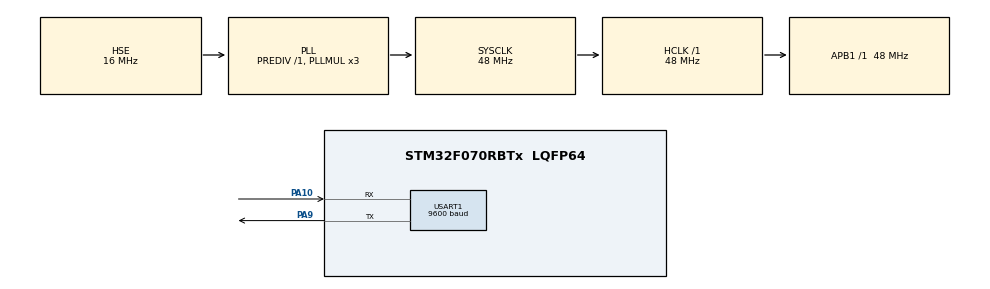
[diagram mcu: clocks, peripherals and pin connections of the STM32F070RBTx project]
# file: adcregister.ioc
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Mcu.Family=STM32F0
Mcu.Name=STM32F070RBTx
Mcu.Package=LQFP64
NVIC.USART1_IRQn=true\:0\:0\:false\:false\:true
PA10.Mode=Asynchronous
PA10.Signal=USART1_RX
PA9.Mode=Asynchronous
PA9.Signal=USART1_TX
PF0-OSC_IN.Mode=HSE-External-Oscillator
PF0-OSC_IN.Signal=RCC_OSC_IN
PF1-OSC_OUT.Mode=HSE-External-Oscillator
PF1-OSC_OUT.Signal=RCC_OSC_OUT
ProjectManager.HeapSize=0x200
ProjectManager.StackSize=0x400
ProjectManager.TargetToolchain=MDK-ARM V5
RCC.AHBFreq_Value=48000000
RCC.APB1Freq_Value=48000000
RCC.APB1TimFreq_Value=48000000
RCC.HCLKFreq_Value=48000000
RCC.HSE_VALUE=16000000
RCC.PLLMUL=RCC_PLL_MUL3
RCC.PLLSourceVirtual=RCC_PLLSOURCE_HSE
RCC.SYSCLKFreq_VALUE=48000000
RCC.SYSCLKSource=RCC_SYSCLKSOURCE_PLLCLK
USART1.BaudRate=9600
USART1.VirtualMode-Asynchronous=VM_ASYNC
USART1.WordLength=WORDLENGTH_8B
board=adcregister

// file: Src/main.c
/**
  ******************************************************************************
  * File Name          : main.c
  * Description        : Main program body
  ******************************************************************************
  ** This notice applies to any and all portions of this file
  * that are not between comment pairs USER CODE BEGIN and
  * USER CODE END. Other portions of this file, whether
  * inserted by the user or by software development tools
  * are owned by their respective copyright owners.
  *
  * COPYRIGHT(c) 2017 STMicroelectronics
  *
  * Redistribution and use in source and binary forms, with or without modification,
  * are permitted provided that the following conditions are met:
  *   1. Redistributions of source code must retain the above copyright notice,
  *      this list of conditions and the following disclaimer.
  *   2. Redistributions in binary form must reproduce the above copyright notice,
  *      this list of conditions and the following disclaimer in the documentation
  *      and/or other materials provided with the distribution.
  *   3. Neither the name of STMicroelectronics nor the names of its contributors
  *      may be used to endorse or promote products derived from this software
  *      without specific prior written permission.
  *
  * THIS SOFTWARE IS PROVIDED BY THE COPYRIGHT HOLDERS AND CONTRIBUTORS "AS IS"
  * AND ANY EXPRESS OR IMPLIED WARRANTIES, INCLUDING, BUT NOT LIMITED TO, THE
  * IMPLIED WARRANTIES OF MERCHANTABILITY AND FITNESS FOR A PARTICULAR PURPOSE ARE
  * DISCLAIMED. IN NO EVENT SHALL THE COPYRIGHT HOLDER OR CONTRIBUTORS BE LIABLE
  * FOR ANY DIRECT, INDIRECT, INCIDENTAL, SPECIAL, EXEMPLARY, OR CONSEQUENTIAL
  * DAMAGES (INCLUDING, BUT NOT LIMITED TO, PROCUREMENT OF SUBSTITUTE GOODS OR
  * SERVICES; LOSS OF USE, DATA, OR PROFITS; OR BUSINESS INTERRUPTION) HOWEVER
  * CAUSED AND ON ANY THEORY OF LIABILITY, WHETHER IN CONTRACT, STRICT LIABILITY,
  * OR TORT (INCLUDING NEGLIGENCE OR OTHERWISE) ARISING IN ANY WAY OUT OF THE USE
  * OF THIS SOFTWARE, EVEN IF ADVISED OF THE POSSIBILITY OF SUCH DAMAGE.
  *
  ******************************************************************************
  */
#include "main.h"
#include "stm32f0xx_hal.h"

UART_HandleTypeDef huart1;

/* USER CODE BEGIN PV */
/* Private variables ---------------------------------------------------------*/
int datain[10],len=0;
unsigned char buffer[100];
/* USER CODE END PV */

void SystemClock_Config(void);
static void MX_GPIO_Init(void);
static void MX_USART1_UART_Init(void);

/* USER CODE BEGIN PFP */
/* Private function prototypes -----------------------------------------------*/

/* USER CODE END PFP */

int main(void)
{

  /* MCU Configuration----------------------------------------------------------*/

  /* Reset of all peripherals, Initializes the Flash interface and the Systick. */
  HAL_Init();

  /* Configure the system clock */
  SystemClock_Config();

  /* Initialize all configured peripherals */
  MX_GPIO_Init();
  MX_USART1_UART_Init();

  /* USER CODE BEGIN 2 */

ADC1 ->CR =0X00000000;  //disable adc start
ADC1 ->CFGR1=0X00002000;  // disable watchdog
ADC1 ->CFGR2=0X00000000;
ADC1 ->SMPR=0X00000000;
ADC1 ->CHSELR=0X00000003;
ADC1 ->CR =0X00000005;   //start adc

  /* USER CODE END 2 */

  /* Infinite loop */
  while (1)
  {

  /* USER CODE BEGIN 3 */
if((ADC1 ->ISR) & 0x00000004)
{

	ADC1 ->ISR &= (~0x00000004);
	if(ADC1 ->CHSELR==0x00000001)
	{
	datain[0] = ADC1->DR;
	}
}
sprintf(buffer,"Value is %d",datain[0]);
len=strlen(buffer);
HAL_UART_Transmit(&huart1,buffer,len,10);
HAL_UART_Transmit(&huart1,"\r\n",1,10);
HAL_Delay(200);
  }
  /* USER CODE END 3 */

}

/** System Clock Configuration
*/
void SystemClock_Config(void)
{

  RCC_OscInitTypeDef RCC_OscInitStruct;
  RCC_ClkInitTypeDef RCC_ClkInitStruct;
  RCC_PeriphCLKInitTypeDef PeriphClkInit;

    /**Initializes the CPU, AHB and APB busses clocks
    */
  RCC_OscInitStruct.OscillatorType = RCC_OSCILLATORTYPE_HSE;
  RCC_OscInitStruct.HSEState = RCC_HSE_ON;
  RCC_OscInitStruct.HSIState = RCC_HSI_ON;
  RCC_OscInitStruct.PLL.PLLState = RCC_PLL_ON;
  RCC_OscInitStruct.PLL.PLLSource = RCC_PLLSOURCE_HSE;
  RCC_OscInitStruct.PLL.PLLMUL = RCC_PLL_MUL3;
  RCC_OscInitStruct.PLL.PREDIV = RCC_PREDIV_DIV1;
  if (HAL_RCC_OscConfig(&RCC_OscInitStruct) != HAL_OK)
  {
    _Error_Handler(__FILE__, __LINE__);
  }

    /**Initializes the CPU, AHB and APB busses clocks
    */
  RCC_ClkInitStruct.ClockType = RCC_CLOCKTYPE_HCLK|RCC_CLOCKTYPE_SYSCLK
                              |RCC_CLOCKTYPE_PCLK1;
  RCC_ClkInitStruct.SYSCLKSource = RCC_SYSCLKSOURCE_PLLCLK;
  RCC_ClkInitStruct.AHBCLKDivider = RCC_SYSCLK_DIV1;
  RCC_ClkInitStruct.APB1CLKDivider = RCC_HCLK_DIV1;

  if (HAL_RCC_ClockConfig(&RCC_ClkInitStruct, FLASH_LATENCY_1) != HAL_OK)
  {
    _Error_Handler(__FILE__, __LINE__);
  }

  PeriphClkInit.PeriphClockSelection = RCC_PERIPHCLK_USART1;
  PeriphClkInit.Usart1ClockSelection = RCC_USART1CLKSOURCE_PCLK1;
  if (HAL_RCCEx_PeriphCLKConfig(&PeriphClkInit) != HAL_OK)
  {
    _Error_Handler(__FILE__, __LINE__);
  }

    /**Configure the Systick interrupt time
    */
  HAL_SYSTICK_Config(HAL_RCC_GetHCLKFreq()/1000);

    /**Configure the Systick
    */
  HAL_SYSTICK_CLKSourceConfig(SYSTICK_CLKSOURCE_HCLK);

  /* SysTick_IRQn interrupt configuration */
  HAL_NVIC_SetPriority(SysTick_IRQn, 0, 0);
}

/* USART1 init function */
static void MX_USART1_UART_Init(void)
{

  huart1.Instance = USART1;
  huart1.Init.BaudRate = 9600;
  huart1.Init.WordLength = UART_WORDLENGTH_8B;
  huart1.Init.StopBits = UART_STOPBITS_1;
  huart1.Init.Parity = UART_PARITY_NONE;
  huart1.Init.Mode = UART_MODE_TX_RX;
  huart1.Init.HwFlowCtl = UART_HWCONTROL_NONE;
  huart1.Init.OverSampling = UART_OVERSAMPLING_16;
  huart1.Init.OneBitSampling = UART_ONE_BIT_SAMPLE_DISABLE;
  huart1.AdvancedInit.AdvFeatureInit = UART_ADVFEATURE_NO_INIT;
  if (HAL_UART_Init(&huart1) != HAL_OK)
  {
    _Error_Handler(__FILE__, __LINE__);
  }

}

/** Configure pins as
        * Analog
        * Input
        * Output
        * EVENT_OUT
        * EXTI
*/
static void MX_GPIO_Init(void)
{

  /* GPIO Ports Clock Enable */
  __HAL_RCC_GPIOF_CLK_ENABLE();
  __HAL_RCC_GPIOA_CLK_ENABLE();

}

void _Error_Handler(char * file, int line)
{
  while(1)
  {
  }
}

/************************ (C) COPYRIGHT STMicroelectronics *****END OF FILE****/
